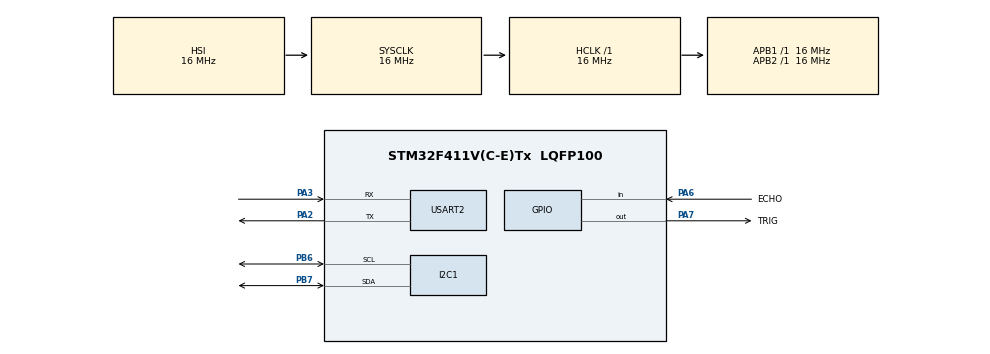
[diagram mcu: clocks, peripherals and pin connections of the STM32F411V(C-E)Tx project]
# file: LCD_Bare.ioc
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Mcu.Family=STM32F4
Mcu.Name=STM32F411V(C-E)Tx
Mcu.Package=LQFP100
NVIC.PriorityGroup=NVIC_PRIORITYGROUP_4
PA13.Mode=Serial_Wire
PA13.Signal=SYS_JTMS-SWDIO
PA14.Mode=Serial_Wire
PA14.Signal=SYS_JTCK-SWCLK
PA2.Mode=Asynchronous
PA2.Signal=USART2_TX
PA3.Mode=Asynchronous
PA3.Signal=USART2_RX
PA6.GPIO_Label=ECHO
PA6.Signal=GPIO_Input
PA7.GPIO_Label=TRIG
PA7.Signal=GPIO_Output
PB6.Mode=I2C
PB6.Signal=I2C1_SCL
PB7.Mode=I2C
PB7.Signal=I2C1_SDA
ProjectManager.HeapSize=0x200
ProjectManager.StackSize=0x400
ProjectManager.TargetToolchain=MDK-ARM V5
RCC.48MHZClocksFreq_Value=48000000
RCC.AHBFreq_Value=16000000
RCC.APB1Freq_Value=16000000
RCC.APB1TimFreq_Value=16000000
RCC.APB2Freq_Value=16000000
RCC.APB2TimFreq_Value=16000000
RCC.CortexFreq_Value=16000000
RCC.HCLKFreq_Value=16000000
RCC.HSE_VALUE=25000000
RCC.HSI_VALUE=16000000
RCC.LSE_VALUE=32768
RCC.SYSCLKFreq_VALUE=16000000
RCC.VCOOutputFreq_Value=192000000
USART2.VirtualMode=VM_ASYNC
VP_TIM4_VS_ClockSourceINT.Mode=Internal
board=custom

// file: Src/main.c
/* USER CODE BEGIN Header */
/**
  ******************************************************************************
  * @file           : main.c
  * @brief          : Main program body
  ******************************************************************************
  * @attention
  *
  * <h2><center>&copy; Copyright (c) 2019 STMicroelectronics.
  * All rights reserved.</center></h2>
  *
  * This software component is licensed by ST under BSD 3-Clause license,
  * the "License"; You may not use this file except in compliance with the
  * License. You may obtain a copy of the License at:
  *                        opensource.org/licenses/BSD-3-Clause
  *
  ******************************************************************************
  */
/* USER CODE END Header */

#include "main.h"

/* USER CODE BEGIN Includes */
#include "i2c-lcd.h"
/* USER CODE END Includes */

/* USER CODE BEGIN PTD */
#define usTIM TIM4
/* USER CODE END PTD */

/* USER CODE BEGIN PD */
#define SLAVE_ADDRESS_LCD 0x4E
/* USER CODE END PD */

I2C_HandleTypeDef hi2c1;

TIM_HandleTypeDef htim4;

UART_HandleTypeDef huart2;

void SystemClock_Config(void);
static void MX_GPIO_Init(void);
static void MX_I2C1_Init(void);
static void MX_USART2_UART_Init(void);
static void MX_TIM4_Init(void);

/* USER CODE BEGIN 0 */
void usDelay(uint32_t uSec);
/* USER CODE END 0 */
uint8_t icFlag = 0;										         					//flag to indicate the completion of
uint8_t captureIdx=0;
volatile uint32_t edge1Time=0, edge2Time=0;				  //rising edge and falling edge variable setup
const float speedOfSound = 0.0343/2;     						 //speed of sound=343 m/s=0.0343 cm/us
float distance;																		//calculated distance in float
uint8_t threshold=5;																//threshold distance
char uartBuf[100];																//UART Buffer Array
uint8_t numTicks=0;

int main(void)
{

  /* MCU Configuration--------------------------------------------------------*/

  /* Reset of all peripherals, Initializes the Flash interface and the Systick. */
  HAL_Init();

  /* USER CODE BEGIN Init */
	lcd_init();
  /* USER CODE END Init */
  /* Configure the system clock */
  SystemClock_Config();

  /* Initialize all configured peripherals */
  MX_GPIO_Init();
  MX_I2C1_Init();
  MX_USART2_UART_Init();
  MX_TIM4_Init();
  /* USER CODE BEGIN 2 */
  lcd_init();
  /* USER CODE END 2 */

  /* Infinite loop */
  /* USER CODE BEGIN WHILE */
  while (1)
  {

							HAL_GPIO_WritePin(TRIG_GPIO_Port, TRIG_Pin, GPIO_PIN_RESET);
        	 		usDelay(3);

        	 		//*** START Ultrasonic measure routine ***//
        	 		//1. Output 10 usec TRIG
        	 		HAL_GPIO_WritePin(TRIG_GPIO_Port, TRIG_Pin, GPIO_PIN_SET);
        	 		usDelay(10);
        	 		HAL_GPIO_WritePin(TRIG_GPIO_Port, TRIG_Pin, GPIO_PIN_RESET);

        	 		//2. ECHO signal pulse width calculation using ECHO pin

        			//2. Wait for ECHO pin rising edge
        			while(HAL_GPIO_ReadPin(ECHO_GPIO_Port, ECHO_Pin) == GPIO_PIN_RESET);

        			//3. Start measuring ECHO pulse width in usec
        			numTicks = 0;
        			while(HAL_GPIO_ReadPin(ECHO_GPIO_Port, ECHO_Pin) == GPIO_PIN_SET)
        			{
        				numTicks++;
        				usDelay(2); //2.8usec
        			};

				distance = (numTicks + 0.0f)*2.8*speedOfSound;

							lcd_send_cmd(0x80);
							lcd_send_string("distance in cm is");
							lcd_send_cmd(0xc0);
							lcd_send_data(distance);
  }
  /* USER CODE END 3 */
}

void SystemClock_Config(void)
{
  RCC_OscInitTypeDef RCC_OscInitStruct = {0};
  RCC_ClkInitTypeDef RCC_ClkInitStruct = {0};

  /** Configure the main internal regulator output voltage
  */
  __HAL_RCC_PWR_CLK_ENABLE();
  __HAL_PWR_VOLTAGESCALING_CONFIG(PWR_REGULATOR_VOLTAGE_SCALE1);
  /** Initializes the CPU, AHB and APB busses clocks
  */
  RCC_OscInitStruct.OscillatorType = RCC_OSCILLATORTYPE_HSI;
  RCC_OscInitStruct.HSIState = RCC_HSI_ON;
  RCC_OscInitStruct.HSICalibrationValue = RCC_HSICALIBRATION_DEFAULT;
  RCC_OscInitStruct.PLL.PLLState = RCC_PLL_NONE;
  if (HAL_RCC_OscConfig(&RCC_OscInitStruct) != HAL_OK)
  {
    Error_Handler();
  }
  /** Initializes the CPU, AHB and APB busses clocks
  */
  RCC_ClkInitStruct.ClockType = RCC_CLOCKTYPE_HCLK|RCC_CLOCKTYPE_SYSCLK
                              |RCC_CLOCKTYPE_PCLK1|RCC_CLOCKTYPE_PCLK2;
  RCC_ClkInitStruct.SYSCLKSource = RCC_SYSCLKSOURCE_HSI;
  RCC_ClkInitStruct.AHBCLKDivider = RCC_SYSCLK_DIV1;
  RCC_ClkInitStruct.APB1CLKDivider = RCC_HCLK_DIV1;
  RCC_ClkInitStruct.APB2CLKDivider = RCC_HCLK_DIV1;

  if (HAL_RCC_ClockConfig(&RCC_ClkInitStruct, FLASH_LATENCY_0) != HAL_OK)
  {
    Error_Handler();
  }
}

static void MX_I2C1_Init(void)
{

  hi2c1.Instance = I2C1;
  hi2c1.Init.ClockSpeed = 100000;
  hi2c1.Init.DutyCycle = I2C_DUTYCYCLE_2;
  hi2c1.Init.OwnAddress1 = 0;
  hi2c1.Init.AddressingMode = I2C_ADDRESSINGMODE_7BIT;
  hi2c1.Init.DualAddressMode = I2C_DUALADDRESS_DISABLE;
  hi2c1.Init.OwnAddress2 = 0;
  hi2c1.Init.GeneralCallMode = I2C_GENERALCALL_DISABLE;
  hi2c1.Init.NoStretchMode = I2C_NOSTRETCH_DISABLE;
  if (HAL_I2C_Init(&hi2c1) != HAL_OK)
  {
    Error_Handler();
  }

}

static void MX_TIM4_Init(void)
{

  TIM_ClockConfigTypeDef sClockSourceConfig = {0};
  TIM_MasterConfigTypeDef sMasterConfig = {0};

  htim4.Instance = TIM4;
  htim4.Init.Prescaler = 0;
  htim4.Init.CounterMode = TIM_COUNTERMODE_UP;
  htim4.Init.Period = 0;
  htim4.Init.ClockDivision = TIM_CLOCKDIVISION_DIV1;
  htim4.Init.AutoReloadPreload = TIM_AUTORELOAD_PRELOAD_DISABLE;
  if (HAL_TIM_Base_Init(&htim4) != HAL_OK)
  {
    Error_Handler();
  }
  sClockSourceConfig.ClockSource = TIM_CLOCKSOURCE_INTERNAL;
  if (HAL_TIM_ConfigClockSource(&htim4, &sClockSourceConfig) != HAL_OK)
  {
    Error_Handler();
  }
  sMasterConfig.MasterOutputTrigger = TIM_TRGO_RESET;
  sMasterConfig.MasterSlaveMode = TIM_MASTERSLAVEMODE_DISABLE;
  if (HAL_TIMEx_MasterConfigSynchronization(&htim4, &sMasterConfig) != HAL_OK)
  {
    Error_Handler();
  }

}

static void MX_USART2_UART_Init(void)
{

  huart2.Instance = USART2;
  huart2.Init.BaudRate = 115200;
  huart2.Init.WordLength = UART_WORDLENGTH_8B;
  huart2.Init.StopBits = UART_STOPBITS_1;
  huart2.Init.Parity = UART_PARITY_NONE;
  huart2.Init.Mode = UART_MODE_TX_RX;
  huart2.Init.HwFlowCtl = UART_HWCONTROL_NONE;
  huart2.Init.OverSampling = UART_OVERSAMPLING_16;
  if (HAL_UART_Init(&huart2) != HAL_OK)
  {
    Error_Handler();
  }

}

static void MX_GPIO_Init(void)
{
  GPIO_InitTypeDef GPIO_InitStruct = {0};

  /* GPIO Ports Clock Enable */
  __HAL_RCC_GPIOA_CLK_ENABLE();
  __HAL_RCC_GPIOB_CLK_ENABLE();

  /*Configure GPIO pin Output Level */
  HAL_GPIO_WritePin(TRIG_GPIO_Port, TRIG_Pin, GPIO_PIN_RESET);

  /*Configure GPIO pin : ECHHO_Pin */
  GPIO_InitStruct.Pin = ECHO_Pin;
  GPIO_InitStruct.Mode = GPIO_MODE_INPUT;
  GPIO_InitStruct.Pull = GPIO_NOPULL;
  HAL_GPIO_Init(ECHO_GPIO_Port, &GPIO_InitStruct);

  /*Configure GPIO pin : TRIG_Pin */
  GPIO_InitStruct.Pin = TRIG_Pin;
  GPIO_InitStruct.Mode = GPIO_MODE_OUTPUT_PP;
  GPIO_InitStruct.Pull = GPIO_NOPULL;
  GPIO_InitStruct.Speed = GPIO_SPEED_FREQ_LOW;
  HAL_GPIO_Init(TRIG_GPIO_Port, &GPIO_InitStruct);

}

void Error_Handler(void)
{
}

void usDelay(uint32_t uSec)
{
	if(uSec < 2)
		uSec = 2;
	usTIM->ARR = uSec - 1; 	/*sets the value in the auto-reload register*/
	usTIM->EGR = 1; 			/*Re-initialises the timer*/
	usTIM->SR &= ~1; 		//Resets the flag              usTIM->SR &=1;
	usTIM->CR1 |= 1; 		//Enables the counter
	while((usTIM->SR&0x0001) != 1);     //if 0 then loop here
	usTIM->SR &= ~(0x0001);
}

void lcd_send_cmd (char cmd)
{
  char data_u, data_l;
	uint8_t data_t[4];
	data_u = (cmd&0xf0);
	data_l = ((cmd<<4)&0xf0);
	data_t[0] = data_u|0x04;  //en=1, rs=0
	data_t[1] = data_u;  //en=0, rs=0
	data_t[2] = data_l|0x04;  //en=1, rs=0
	data_t[3] = data_l;  //en=0, rs=0
	HAL_I2C_Master_Transmit (&hi2c1, SLAVE_ADDRESS_LCD,(uint8_t *) data_t, 4, 100);
}

void lcd_send_data (char data)
{
	char data_u, data_l;
	uint8_t data_t[50];
	data_u = (data&0xf0);
	data_l = ((data<<4)&0xf0);
	data_t[0] = data_u|0x05;  //en=1, rs=1
	data_t[1] = data_u|0x01;  //en=0, rs=1
	data_t[2] = data_l|0x05;  //en=1, rs=1
	data_t[3] = data_l|0x01;  //en=0, rs=1
	HAL_I2C_Master_Transmit (&hi2c1, SLAVE_ADDRESS_LCD,(uint8_t *) data_t, 50, 100);
}

void lcd_init (void)
{
	lcd_send_cmd (0x02);
	lcd_send_cmd (0x28);
	lcd_send_cmd (0x0c);
	lcd_send_cmd (0x80);
}

void lcd_send_string (char *str)
{
	while (*str)
		lcd_send_data (*str++);
}

/************************ (C) COPYRIGHT STMicroelectronics *****END OF FILE****/
